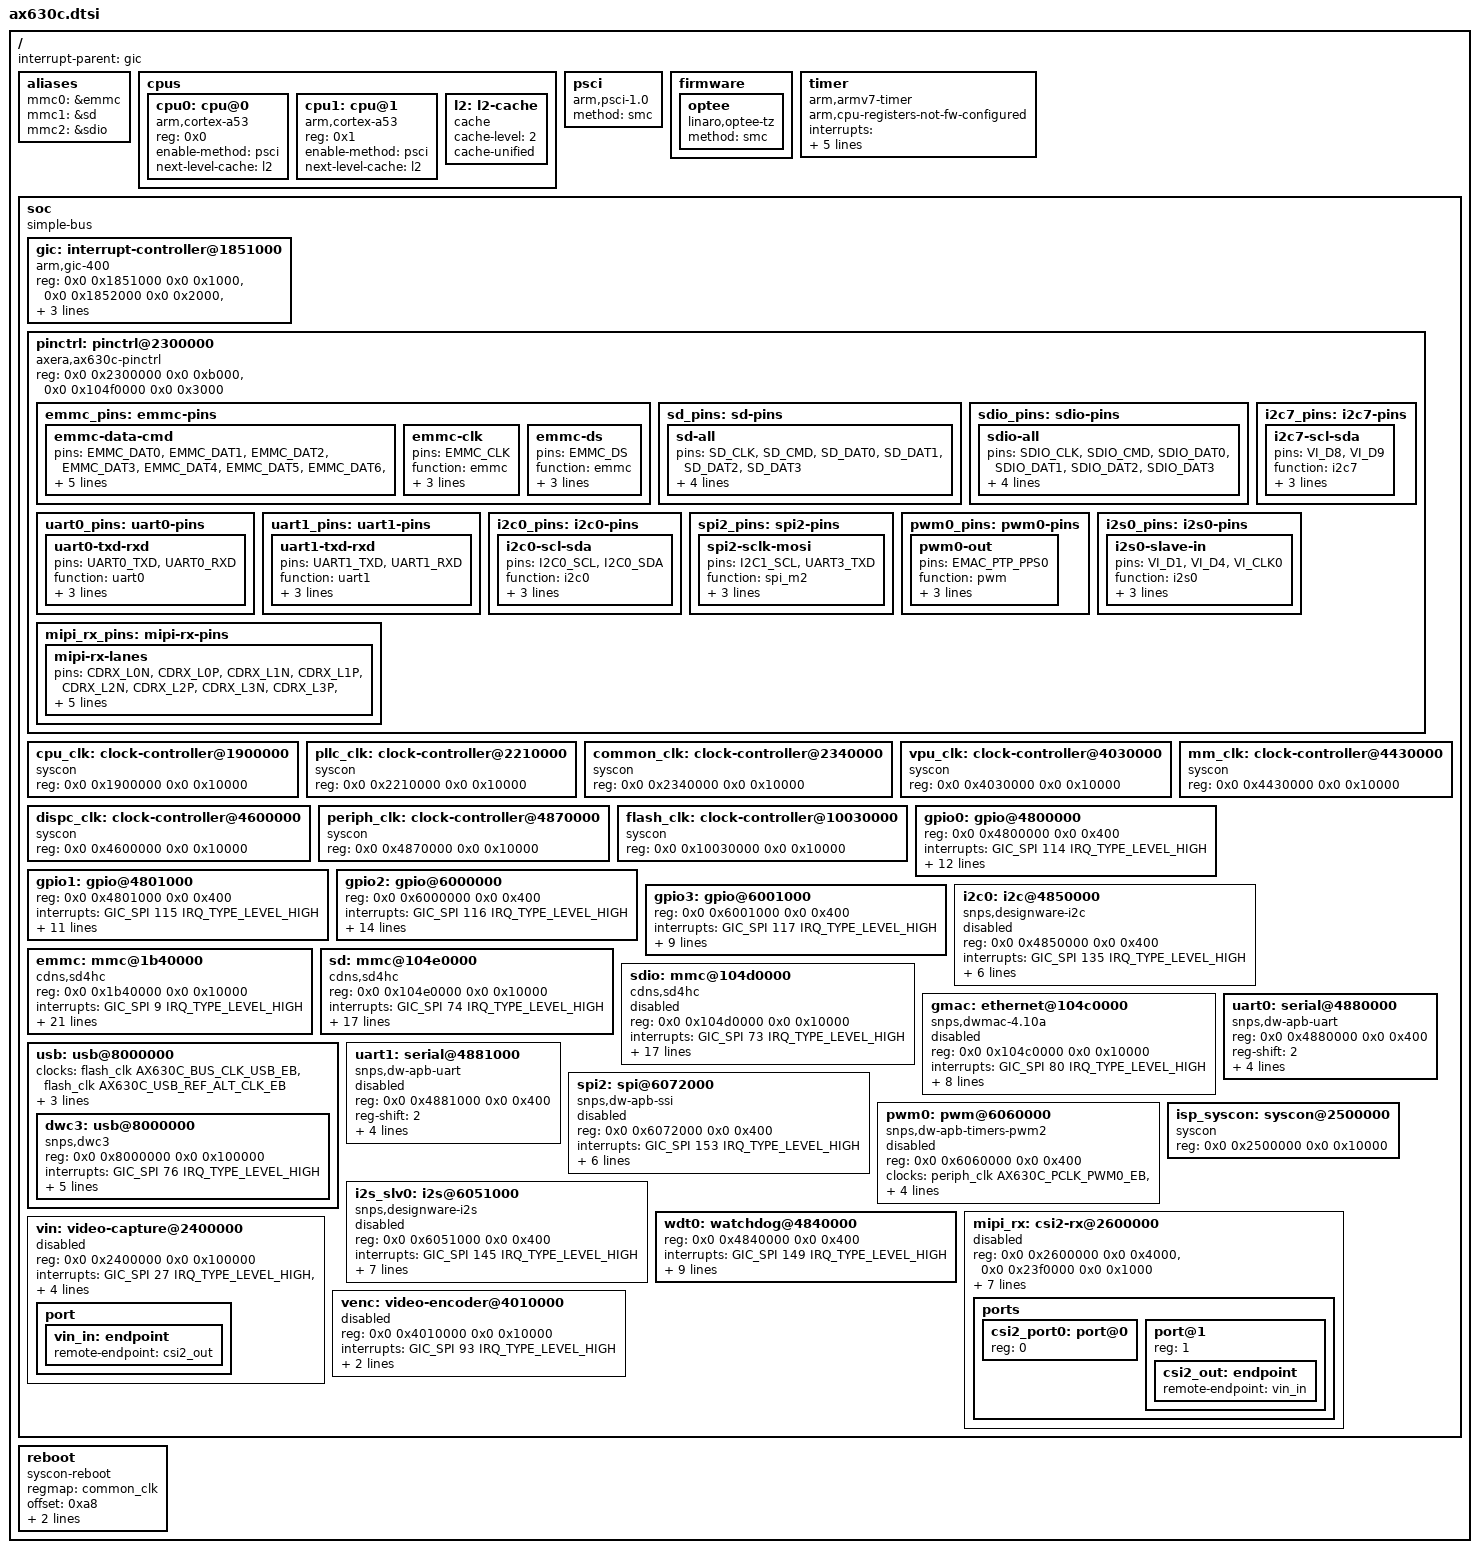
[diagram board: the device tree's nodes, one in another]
// SPDX-License-Identifier: GPL-2.0
/*
 * Axera AX630C (AX620E family) -- minimal mainline SoC description (#74).
 *
 * Written from the vendor GPL device tree
 * (maix_ax620e_sdk_kernel, arch/arm64/boot/dts/axera/AX620E.dtsi) and the
 * inventory in docs/mainline-port.md section 2. Register windows, interrupt
 * numbers and the 24 MHz timer rate are taken verbatim from that source; the
 * bindings are mainline ones.
 *
 * DELIBERATELY MINIMAL. A node arrives with the child issue that ports its
 * driver, because a node whose driver does not exist is a DT that lies. So far
 * that is #76 storage, #77 net, #80 clk/pinctrl, #81 GPIO/I2C and #82 USB;
 * video (#83) and display/audio (#84) are still absent.
 */

#include <dt-bindings/interrupt-controller/arm-gic.h>
#include <dt-bindings/clock/ax630c-clock.h>
#include <dt-bindings/reset/ax630c-reset.h>
#include "ax630c-compat.h"

/ {
	compatible = AX630C_SOC_COMPAT, AX620E_FAMILY_COMPAT;
	interrupt-parent = <&gic>;
	#address-cells = <2>;
	#size-cells = <2>;

	/*
	 * mmc aliases pin the MMC host indices, and on this board that is not
	 * cosmetic -- it decides whether the eMMC has a partition table at all.
	 *
	 * The eMMC's layout comes from the `blkdevparts=mmcblk0:...` clause of
	 * the U-Boot command line (there is no on-disk partition table), and
	 * that clause binds the table to a device NAME. The three SD4HC
	 * instances probe concurrently, so without aliases the eMMC is
	 * sometimes mmc0 and sometimes mmc1 -- and when it loses, `mmcblk0` is
	 * the empty SD slot, the table lands on nothing, and the eMMC comes up
	 * with zero partitions. Measured on hardware during #78: two slot-B
	 * boots out of five came up that way, and stage 1 could not find a
	 * rootfs on a board whose rootfs was perfectly intact.
	 *
	 * With these, mmc_of_parse()'s alias id fixes each host's index, the
	 * eMMC is always mmc0/mmcblk0, and the cmdline table always lands on
	 * it. #76 saw the same silicon behave because it happened to win.
	 */
	aliases {
		mmc0 = &emmc;
		mmc1 = &sd;
		mmc2 = &sdio;
	};

	cpus {
		#address-cells = <1>;
		#size-cells = <0>;

		cpu0: cpu@0 {
			device_type = "cpu";
			compatible = "arm,cortex-a53";
			reg = <0x0>;
			enable-method = "psci";
			next-level-cache = <&l2>;
		};

		cpu1: cpu@1 {
			device_type = "cpu";
			compatible = "arm,cortex-a53";
			reg = <0x1>;
			enable-method = "psci";
			next-level-cache = <&l2>;
		};

		l2: l2-cache {
			compatible = "cache";
			cache-level = <2>;
			cache-unified;
		};
	};

	/*
	 * TF-A 2.7 (plat/axera/ax620e) sits at 0x40040000 and MUST stay
	 * reserved no-map, or secondary CPU bring-up dies. Its plat_psci_ops
	 * implements no system_off/system_reset -- reboot comes from the
	 * watchdog restart handler instead (#75).
	 */
	psci {
		compatible = "arm,psci-1.0";
		method = "smc";
	};

	firmware {
		optee {
			compatible = "linaro,optee-tz";
			method = "smc";
		};
	};

	/*
	 * arm,armv7-timer with arm,cpu-registers-not-fw-configured: the
	 * firmware does not program CNTFRQ, so the 24 MHz clock-frequency here
	 * is load-bearing. Both properties are carried over verbatim.
	 */
	timer {
		compatible = "arm,armv7-timer";
		arm,cpu-registers-not-fw-configured;
		interrupts = <GIC_PPI 13 (GIC_CPU_MASK_SIMPLE(2) | IRQ_TYPE_LEVEL_HIGH)>,
			     <GIC_PPI 14 (GIC_CPU_MASK_SIMPLE(2) | IRQ_TYPE_LEVEL_HIGH)>,
			     <GIC_PPI 11 (GIC_CPU_MASK_SIMPLE(2) | IRQ_TYPE_LEVEL_HIGH)>,
			     <GIC_PPI 10 (GIC_CPU_MASK_SIMPLE(2) | IRQ_TYPE_LEVEL_HIGH)>;
		clock-frequency = <24000000>;
	};

	/*
	 * No PMU node. The vendor tree has none, so the PMU SPI numbers are
	 * simply not known from source -- inventing them would be worse than
	 * having no perf. Determine them on hardware and add the node then.
	 */

	soc {
		compatible = "simple-bus";
		#address-cells = <2>;
		#size-cells = <2>;
		ranges;

		/*
		 * GIC-400 (GICv2). The vendor node gives GICC a 0x1000 window;
		 * mainline's arm,gic-400 binding wants 0x2000 so GICC_DIR at
		 * +0x1000 is mapped for split EOI. 0x1852000 + 0x2000 stops
		 * short of GICH at 0x1854000, so widening it is safe.
		 */
		gic: interrupt-controller@1851000 {
			compatible = "arm,gic-400";
			reg = <0x0 0x1851000 0x0 0x1000>,	/* GICD */
			      <0x0 0x1852000 0x0 0x2000>,	/* GICC */
			      <0x0 0x1854000 0x0 0x2000>,	/* GICH */
			      <0x0 0x1856000 0x0 0x2000>;	/* GICV */
			interrupt-controller;
			#interrupt-cells = <3>;
		};

		/*
		 * Clock controllers (#80). Grouped rather than scattered
		 * through the address ordering, because they are one driver
		 * and one data model: the register maps and per-clock tables
		 * are docs/reference/mainline/clk-model-20260906.md, which was
		 * reconciled clock by clock against a running device.
		 *
		 * Every window is 64 KiB and every one is also a syscon. The
		 * eight here register 279 clocks between them; the vendor's
		 * ninth ("isp") is omitted because no driver has ever
		 * implemented it, as is the whole ddr namespace.
		 *
		 * Seven of the eight also hand out reset lines -- 148 of them,
		 * one bit each in the words next to the clock gates, described
		 * in docs/reference/mainline/reset-model-20260906.md. They get
		 * #reset-cells here rather than reset-controller@ nodes of
		 * their own: a second node over the same window would mean a
		 * second regmap and a second lock over registers the clock
		 * driver read-modify-writes. pllc has no reset lines.
		 *
		 * No node carries assigned-clocks yet. The bootloader leaves
		 * the tree in a working state -- CPUPLL locked at 1.2 GHz, the
		 * UART fed from cpll_208m, the Ethernet refs already selected
		 * -- and a first mainline boot should change nothing it does
		 * not have to.
		 */
		/*
		 * Pin controller (#80). 111 pads in two windows that form one
		 * logical offset space; the driver keeps each pad's offset
		 * local to its own window rather than reproducing the vendor's
		 * SECOND_OFFSET arithmetic.
		 *
		 * The states below are transcribed from the vendor boot
		 * chain's own pad table (pinctrl-model section 4.2), which is
		 * what actually programs these pads today: 133 writes, 111 of
		 * them one per pad, issued by U-Boot before Linux starts. They
		 * are therefore no-ops in value on this board -- the point of
		 * writing them down is that Linux now OWNS the pads it uses,
		 * so a pad cannot be silently re-muxed out from under a driver
		 * and a second claimant gets -EBUSY instead of a corrupted
		 * bus. Only nodes that exist get a state; the rest arrive with
		 * their drivers (#77 RGMII, #83/#84 video). USB
		 * arrived without one on purpose -- its only pin group is the
		 * host-mode OVRCUR/POWER_EN pair, which this board does not
		 * wire; see the usb node below.
		 *
		 * Three rules the driver enforces, worth knowing before adding
		 * one:
		 *
		 *  - Config properties must name `pins`, never `groups`: the
		 *    driver implements pin_config_set and not
		 *    pin_config_group_set, and the core fails the whole state
		 *    (and the consumer's probe) on the latter.
		 *  - The multi-pad groups are wider than they look. "uart0"
		 *    includes two RGMII pads as CTS/RTS and "uart1" includes
		 *    EMMC_PWR_EN and BOND2, so the UART states below name
		 *    their two pads explicitly.
		 *  - drive-strength is the pad's raw 4-bit code, not mA. The
		 *    mA mapping is not known for this SoC.
		 *
		 * axera,dphytx-reset / axera,dphytx-mipien are deliberately
		 * absent, and the syscon holding the MIPI-enable bit has no node
		 * until the video stack lands (#83). That gates set_mux() only:
		 * a CDTX_* pad cannot be moved off function 0 by a pinctrl state
		 * without parking the transmitter first. gpio_request_enable()
		 * does not park, and #81 muxes three of those pads to GPIO
		 * through it on every boot -- which is exactly what the vendor's
		 * own LT6911 driver has always done with a raw register write,
		 * so it is the proven path rather than a shortcut.
		 */
		pinctrl: pinctrl@2300000 {
			compatible = "axera,ax630c-pinctrl";
			reg = <0x0 0x2300000 0x0 0xb000>,
			      <0x0 0x104f0000 0x0 0x3000>;

			/*
			 * eMMC, three electrical variants. EMMC_RESET_N is
			 * deliberately not here: it is not part of function
			 * emmc at all (the pad has no function 0), it is the
			 * card's RST_n driven as GPIO2_A23, and it belongs to
			 * the reset-gpios TODO on the mmc node (#81).
			 *
			 * The vendor's own DT pin group for EMMC_CMD says
			 * pull-DOWN where its boot table writes pull-up. The
			 * boot table wins here: it is what has been running on
			 * this board, and that DT group is one of the ones the
			 * board dts never references.
			 */
			emmc_pins: emmc-pins {
				emmc-data-cmd {
					pins = "EMMC_DAT0", "EMMC_DAT1",
					       "EMMC_DAT2", "EMMC_DAT3",
					       "EMMC_DAT4", "EMMC_DAT5",
					       "EMMC_DAT6", "EMMC_DAT7",
					       "EMMC_CMD";
					function = "emmc";
					drive-strength = <3>;
					bias-pull-up;
					input-schmitt-disable;
				};

				emmc-clk {
					pins = "EMMC_CLK";
					function = "emmc";
					drive-strength = <3>;
					bias-disable;
					input-schmitt-disable;
				};

				/* Data strobe: pulled down, per the boot table. */
				emmc-ds {
					pins = "EMMC_DS";
					function = "emmc";
					drive-strength = <3>;
					bias-pull-down;
					input-schmitt-disable;
				};
			};

			sd_pins: sd-pins {
				sd-all {
					pins = "SD_CLK", "SD_CMD", "SD_DAT0",
					       "SD_DAT1", "SD_DAT2", "SD_DAT3";
					function = "sd";
					drive-strength = <5>;
					bias-disable;
					input-schmitt-disable;
				};
			};

			sdio_pins: sdio-pins {
				sdio-all {
					pins = "SDIO_CLK", "SDIO_CMD",
					       "SDIO_DAT0", "SDIO_DAT1",
					       "SDIO_DAT2", "SDIO_DAT3";
					function = "sdio";
					drive-strength = <8>;
					bias-disable;
					input-schmitt-disable;
				};
			};

			/*
			 * Two pads each, not the four-pad "uart0"/"uart1"
			 * groups: this board wires no flow control, and those
			 * groups would claim two RGMII pads and two pads the
			 * board uses for other things.
			 */
			uart0_pins: uart0-pins {
				uart0-txd-rxd {
					pins = "UART0_TXD", "UART0_RXD";
					function = "uart0";
					drive-strength = <3>;
					bias-pull-up;
					input-schmitt-disable;
				};
			};

			uart1_pins: uart1-pins {
				uart1-txd-rxd {
					pins = "UART1_TXD", "UART1_RXD";
					function = "uart1";
					drive-strength = <3>;
					bias-pull-up;
					input-schmitt-disable;
				};
			};

			/*
			 * The two I2C buses this board actually uses: i2c0
			 * carries the LT6911UXC HDMI-RX bridge, i2c7 the
			 * touch controller. These are exactly the states the
			 * vendor board dts /delete-property/s -- along with
			 * the "gpio" bus-recovery state, which left its
			 * i2c-gpio recovery claiming GPIOs it could never
			 * mux, so recovery bit-banged pads still wired to the
			 * I2C controller.
			 *
			 * Declared but not referenced: there is no I2C
			 * controller node until that driver is ported, and a
			 * node whose driver does not exist is a DT that lies.
			 * Bus recovery wants the matching "gpio" state, which
			 * needs #81. i2c1 and i2c6 are deliberately absent:
			 * their pads belong to spi1/spi2/i2s_slv0 on this
			 * board, and with strict mux enforcement the second
			 * claimant would simply fail.
			 */
			i2c0_pins: i2c0-pins {
				i2c0-scl-sda {
					pins = "I2C0_SCL", "I2C0_SDA";
					function = "i2c0";
					drive-strength = <3>;
					bias-pull-up;
					input-schmitt-disable;
				};
			};

			i2c7_pins: i2c7-pins {
				i2c7-scl-sda {
					pins = "VI_D8", "VI_D9";
					function = "i2c7";
					drive-strength = <3>;
					bias-pull-up;
					input-schmitt-disable;
				};
			};

			/*
			 * The MIPI CSI-2 receiver's twelve lane pads (#83).
			 * Six differential pairs; the board uses four of them
			 * for data and one for the clock, and the D-PHY's own
			 * lane-swap fields decide which is which -- so the
			 * whole group is claimed, not a subset.
			 *
			 * Every value here reproduces what the boot chain's own
			 * pad table writes: 0x00000000, which is mux 0
			 * (dphy_rx, the pads' only real function), drive code
			 * 0, no pull, no schmitt. That is also the pads' reset
			 * state, so this state is a no-op in value on this
			 * board. The point is OWNERSHIP: on 4.19 the vendor
			 * boot chain and then ax_pinmux replayed the SDK pad
			 * table, and nothing replays it on mainline.
			 *
			 * VI_D7 is deliberately absent, and so is every other
			 * VI_* pad. VI_D7 carries SW_PWR (GPIO0_A7) on this
			 * board -- the vendor capture stack re-muxed it at
			 * every pipeline init and that is the whole SW_PWR
			 * trap. The MIPI path does not need it.
			 */
			/*
			 * SPI2, the mini-display's bus (#84). TWO pads, not
			 * four: the panel is write-only, so MISO is not
			 * claimed, and the chip select is a GPIO -- the pad
			 * that would carry SPI_M2_CS0 (I2C1_SDA) is muxed to
			 * GPIO0_A27 by the GPIO claim instead, which is what
			 * the vendor board does too.
			 *
			 * Drive strength 3 and a pull-up on both, reproducing
			 * the boot chain's own pad table. The SSI clock is
			 * 208 MHz and the panel is asked for 80, so the bus
			 * actually runs at 52 -- spi-dw's divisor is even.
			 */
			spi2_pins: spi2-pins {
				spi2-sclk-mosi {
					pins = "I2C1_SCL", "UART3_TXD";
					function = "spi_m2";
					drive-strength = <3>;
					bias-pull-up;
					input-schmitt-disable;
				};
			};

			/*
			 * The backlight's PWM output (#84): PWM0 channel 0 on
			 * its alternate pad (function PWM0_M), which is what
			 * the vendor group `emac_ptp_pps0_pwm0_m_pins` names.
			 *
			 * THIS ONE IS NOT A NO-OP IN VALUE, unlike most of the
			 * states in this file. The boot chain's own pad table
			 * leaves EMAC_PTP_PPS0 muxed to GPIO1_A8
			 * (0x104F000C = 0x00060003) and the vendor KERNEL is
			 * what moves it to PWM at probe -- measured on the
			 * running vendor system as 0x00020003, which is
			 * exactly what this state writes. Nothing replays that
			 * on mainline, so without this group the backlight pad
			 * stays an unclaimed GPIO and the panel is dark with a
			 * PWM that reports itself working.
			 *
			 * No pull: the pad drives a load, it is never read.
			 */
			pwm0_pins: pwm0-pins {
				pwm0-out {
					pins = "EMAC_PTP_PPS0";
					function = "pwm";
					drive-strength = <3>;
					bias-disable;
					input-schmitt-disable;
				};
			};

			/*
			 * The HDMI audio port's three pads (#84). Capture
			 * only, so no DOUT and no MCLK: the LT6911UXC is the
			 * bit-clock and frame master and the SoC is a pure
			 * slave.
			 *
			 * DIN1, not DIN0. The peripheral syscon's audio
			 * crossbar word puts this stream on the slave block's
			 * RX channel 1 (see the i2s node below), and the pad
			 * that feeds channel 1 is VI_D4.
			 *
			 * These three pads are VI_* like SW_PWR's VI_D7, and
			 * the same rule applies: claim only what is used, and
			 * never VI_D7.
			 */
			i2s0_pins: i2s0-pins {
				i2s0-slave-in {
					pins = "VI_D1", "VI_D4", "VI_CLK0";
					function = "i2s0";
					drive-strength = <3>;
					bias-disable;
					input-schmitt-disable;
				};
			};

			mipi_rx_pins: mipi-rx-pins {
				mipi-rx-lanes {
					pins = "CDRX_L0N", "CDRX_L0P",
					       "CDRX_L1N", "CDRX_L1P",
					       "CDRX_L2N", "CDRX_L2P",
					       "CDRX_L3N", "CDRX_L3P",
					       "CDRX_L4N", "CDRX_L4P",
					       "CDRX_L5N", "CDRX_L5P";
					function = "dphy_rx";
					drive-strength = <0>;
					bias-disable;
					input-schmitt-disable;
				};
			};
		};

		cpu_clk: clock-controller@1900000 {
			compatible = AX630C_CPU_CLK_COMPAT, "syscon";
			reg = <0x0 0x1900000 0x0 0x10000>;
			#clock-cells = <1>;
			#reset-cells = <1>;
		};

		pllc_clk: clock-controller@2210000 {
			compatible = AX630C_PLLC_CLK_COMPAT, "syscon";
			reg = <0x0 0x2210000 0x0 0x10000>;
			#clock-cells = <1>;
		};

		common_clk: clock-controller@2340000 {
			compatible = AX630C_COMMON_CLK_COMPAT, "syscon";
			reg = <0x0 0x2340000 0x0 0x10000>;
			#clock-cells = <1>;
			#reset-cells = <1>;
		};

		vpu_clk: clock-controller@4030000 {
			compatible = AX630C_VPU_CLK_COMPAT, "syscon";
			reg = <0x0 0x4030000 0x0 0x10000>;
			#clock-cells = <1>;
			#reset-cells = <1>;
		};

		mm_clk: clock-controller@4430000 {
			compatible = AX630C_MM_CLK_COMPAT, "syscon";
			reg = <0x0 0x4430000 0x0 0x10000>;
			#clock-cells = <1>;
			#reset-cells = <1>;
		};

		dispc_clk: clock-controller@4600000 {
			compatible = AX630C_DISPC_CLK_COMPAT, "syscon";
			reg = <0x0 0x4600000 0x0 0x10000>;
			#clock-cells = <1>;
			#reset-cells = <1>;
		};

		periph_clk: clock-controller@4870000 {
			compatible = AX630C_PERIPH_CLK_COMPAT, "syscon";
			reg = <0x0 0x4870000 0x0 0x10000>;
			#clock-cells = <1>;
			#reset-cells = <1>;
		};

		flash_clk: clock-controller@10030000 {
			compatible = AX630C_FLASH_CLK_COMPAT, "syscon";
			reg = <0x0 0x10030000 0x0 0x10000>;
			#clock-cells = <1>;
			#reset-cells = <1>;
		};

		/*
		 * GPIO (#81). Four identical 32-line controllers; the block is
		 * DesignWare in its register names only, so gpio-dwapb cannot
		 * bind and drivers/gpio/gpio-ax630c.c exists.
		 *
		 * gpio-ranges is the load-bearing property here, not
		 * decoration. It is what makes gpiochip_generic_request() reach
		 * the pin controller's gpio_request_enable(), which programs
		 * the pad's mux -- the root fix for the SW_PWR trap, where
		 * exporting a GPIO never reprogrammed the pad and the value
		 * register echoed a latch that no longer reached a ball. The
		 * mapping is not an identity: 97 of the 111 pads reach a GPIO
		 * line, in seven runs per controller, and lines outside those
		 * runs exist in the register file but reach no pad. The runs
		 * below are the vendor DT's 97 single-line entries collapsed,
		 * pin for pin.
		 *
		 * Two clocks each: "gpio" drives the per-line debounce filter
		 * and the interrupt synchroniser, "apb" the register file.
		 * Two resets each, deasserted at probe and never pulsed --
		 * lines on these blocks drive the host's ATX power button and
		 * the HDMI receiver's power rails, so a reset pulse would be a
		 * keystroke nobody pressed.
		 */
		gpio0: gpio@4800000 {
			compatible = AX630C_GPIO_COMPAT;
			reg = <0x0 0x4800000 0x0 0x400>;
			interrupts = <GIC_SPI 114 IRQ_TYPE_LEVEL_HIGH>;
			clocks = <&periph_clk AX630C_CLK_GPIO0_EB>,
				 <&periph_clk AX630C_PCLK_GPIO0_EB>;
			clock-names = "gpio", "apb";
			resets = <&periph_clk AX630C_RST_PERIPH_AX_GPIO0_GPIO_PRST>,
				 <&periph_clk AX630C_RST_PERIPH_AX_GPIO0_GPIO>;
			reset-names = "apb", "gpio";
			gpio-controller;
			#gpio-cells = <2>;
			ngpios = <32>;
			gpio-ranges = <&pinctrl 0 0 11>, <&pinctrl 11 79 4>,
				      <&pinctrl 15 87 4>, <&pinctrl 19 62 1>,
				      <&pinctrl 20 60 1>, <&pinctrl 21 92 3>,
				      <&pinctrl 24 11 8>;
			interrupt-controller;
			#interrupt-cells = <2>;
			status = "okay";
		};

		gpio1: gpio@4801000 {
			compatible = AX630C_GPIO_COMPAT;
			reg = <0x0 0x4801000 0x0 0x400>;
			interrupts = <GIC_SPI 115 IRQ_TYPE_LEVEL_HIGH>;
			clocks = <&periph_clk AX630C_CLK_GPIO1_EB>,
				 <&periph_clk AX630C_PCLK_GPIO1_EB>;
			clock-names = "gpio", "apb";
			resets = <&periph_clk AX630C_RST_PERIPH_AX_GPIO1_GPIO_PRST>,
				 <&periph_clk AX630C_RST_PERIPH_AX_GPIO1_GPIO>;
			reset-names = "apb", "gpio";
			gpio-controller;
			#gpio-cells = <2>;
			ngpios = <32>;
			gpio-ranges = <&pinctrl 0 19 4>, <&pinctrl 4 95 4>,
				      <&pinctrl 8 23 4>, <&pinctrl 12 33 12>,
				      <&pinctrl 24 27 6>, <&pinctrl 30 63 2>;
			interrupt-controller;
			#interrupt-cells = <2>;
			status = "okay";
		};

		gpio2: gpio@6000000 {
			compatible = AX630C_GPIO_COMPAT;
			reg = <0x0 0x6000000 0x0 0x400>;
			interrupts = <GIC_SPI 116 IRQ_TYPE_LEVEL_HIGH>;
			clocks = <&periph_clk AX630C_CLK_GPIO2_EB>,
				 <&periph_clk AX630C_PCLK_GPIO2_EB>;
			clock-names = "gpio", "apb";
			resets = <&periph_clk AX630C_RST_PERIPH_AX_GPIO2_GPIO_PRST>,
				 <&periph_clk AX630C_RST_PERIPH_AX_GPIO2_GPIO>;
			reset-names = "apb", "gpio";
			gpio-controller;
			#gpio-cells = <2>;
			ngpios = <32>;
			/* 30 pads, not 32: lines 30 and 31 reach nothing. */
			gpio-ranges = <&pinctrl 0 65 4>, <&pinctrl 4 45 6>,
				      <&pinctrl 10 69 10>, <&pinctrl 20 56 1>,
				      <&pinctrl 21 54 1>, <&pinctrl 22 55 1>,
				      <&pinctrl 23 52 1>, <&pinctrl 24 51 1>,
				      <&pinctrl 25 53 1>, <&pinctrl 26 57 3>,
				      <&pinctrl 29 61 1>;
			interrupt-controller;
			#interrupt-cells = <2>;
			status = "okay";
		};

		gpio3: gpio@6001000 {
			compatible = AX630C_GPIO_COMPAT;
			reg = <0x0 0x6001000 0x0 0x400>;
			interrupts = <GIC_SPI 117 IRQ_TYPE_LEVEL_HIGH>;
			clocks = <&periph_clk AX630C_CLK_GPIO3_EB>,
				 <&periph_clk AX630C_PCLK_GPIO3_EB>;
			clock-names = "gpio", "apb";
			resets = <&periph_clk AX630C_RST_PERIPH_AX_GPIO3_GPIO_PRST>,
				 <&periph_clk AX630C_RST_PERIPH_AX_GPIO3_GPIO>;
			reset-names = "apb", "gpio";
			gpio-controller;
			#gpio-cells = <2>;
			ngpios = <32>;
			/* Three pads, on lines 1-3. Line 0 reaches nothing. */
			gpio-ranges = <&pinctrl 1 84 3>;
			interrupt-controller;
			#interrupt-cells = <2>;
			status = "okay";
		};

		/*
		 * I2C0 (#81), the bus the LT6911UXC HDMI receiver lives on.
		 * Stock Synopsys DesignWare; mainline i2c-designware-platform
		 * binds the unmodified compatible.
		 *
		 * The vendor driver hard-codes 208 MHz as its timing input and
		 * programs the source mux itself. Naming the clock instead
		 * means i2c-designware computes HCNT/LCNT from
		 * clk_get_rate(), so the bus is right whatever source firmware
		 * selected -- and clk_i2c_sel is registered precisely so that
		 * rate is a fact rather than a constant.
		 *
		 * The "gpio" bus-recovery state is deliberately absent. The
		 * vendor's recovery claims GPIO0_A24/A25 while its pinctrl
		 * states leave those pads on the I2C controller, so it
		 * bit-bangs pads the controller still owns -- recovery that
		 * cannot work. Doing it properly needs scl-gpios/sda-gpios and
		 * a matching pin state, which is worth adding the day a stuck
		 * bus is actually observed.
		 */
		i2c0: i2c@4850000 {
			compatible = "snps,designware-i2c";
			reg = <0x0 0x4850000 0x0 0x400>;
			interrupts = <GIC_SPI 135 IRQ_TYPE_LEVEL_HIGH>;
			clocks = <&periph_clk AX630C_CLK_I2C_MST0_EB>,
				 <&periph_clk AX630C_PCLK_I2C_MST0_EB>;
			clock-names = "ref", "pclk";
			resets = <&periph_clk AX630C_RST_PERIPH_I2C0>;
			pinctrl-names = "default";
			pinctrl-0 = <&i2c0_pins>;
			clock-frequency = <400000>;
			i2c-sda-hold-time-ns = <500>;
			#address-cells = <1>;
			#size-cells = <0>;
			status = "disabled";
		};

		/*
		 * eMMC (#76) -- the boot device. Everything about this node is
		 * argued in docs/reference/mainline/sdhci-model-20260906.md;
		 * the four things a reader will want to know are:
		 *
		 * NO `resets`, deliberately. The SoC does have three reset
		 * lines for this controller (prst/arst/cardrst, cpu syscon
		 * 0x10 bits 12/12/11) but mainline sdhci-cadence reserves the
		 * `resets` property for the CARD's RST_n and binds index 0 to
		 * card_hw_reset. Listing the controller's own APB reset there
		 * makes mmc_hw_reset() -- an error-recovery path -- reset the
		 * host. It would pass a first boot and wedge under I/O error
		 * days later. Firmware leaves all three deasserted (U-Boot
		 * reads the kernel through this controller), so doing nothing
		 * is correct.
		 *
		 * ONE clock. The binding allows exactly one and the driver
		 * takes index 0 unnamed, so it is the card clock. The
		 * controller's own bus gate (AX630C_CLK_EMMC_EB) cannot be
		 * named here and is CLK_IS_CRITICAL in the clock driver.
		 *
		 * NO `sdhci-caps-mask`. The vendor's <0x2 0x03200000> clears
		 * CAN_VDD_330|CAN_VDD_300|CAN_DO_HISPD, all of which the
		 * cap-* properties below then re-add. It is redundant, not
		 * dangerous -- CAPS0 reads 0x176AC8B2 on this silicon, so
		 * CAN_VDD_180 survives the mask and ocr_avail is non-zero
		 * either way (measured 2026-09-06).
		 *
		 * NO cdns,phy-input-delay-mmc-legacy. PHY address 0x06 has no
		 * entry in any driver's property table, vendor included, so
		 * the vendor DT's value has never been applied to this board.
		 * Upstream's schema is unevaluatedProperties:false.
		 *
		 * TODO(#81): cap-mmc-hw-reset + reset-gpios = <&gpio2 23
		 * GPIO_ACTIVE_LOW>. The card's real RST_n is GPIO2_A23, and
		 * with CONFIG_RESET_GPIO the reset core synthesises a
		 * controller over it for free -- but there is no GPIO
		 * controller node until #81, and a phandle to a node that does
		 * not exist does not compile.
		 */
		emmc: mmc@1b40000 {
			compatible = AX630C_SDHCI_COMPAT, "cdns,sd4hc";
			reg = <0x0 0x1b40000 0x0 0x10000>;
			interrupts = <GIC_SPI 9 IRQ_TYPE_LEVEL_HIGH>;
			clocks = <&cpu_clk AX630C_CLK_EMMC_CARD_EB>;
			pinctrl-names = "default";
			pinctrl-0 = <&emmc_pins>;
			bus-width = <8>;
			non-removable;
			no-sd;
			no-sdio;
			disable-wp;
			cap-mmc-highspeed;
			/*
			 * This logs "mmc0: invalid driver type, default to
			 * driver type B" a few times per boot, and that is
			 * correct behaviour, not a defect to chase.
			 * fixed-emmc-driver-type carries an eMMC-spec driver
			 * type (table 206); 4 = 40 ohm. sdhci can only express
			 * the SD host types A/B/C/D = 0..3, so it warns and
			 * uses B -- while the CARD is still programmed to type
			 * 4 through EXT_CSD_HS_TIMING. The vendor's own driver
			 * has the identical limitation, so keeping the property
			 * reproduces the vendor's proven electrical state
			 * exactly; dropping it would quiet the log and change
			 * the card's drive strength.
			 */
			fixed-emmc-driver-type = <4>;
			/*
			 * Pinned to high speed for bring-up, on purpose.
			 * Mainline runs a read-gap tuning step over HRS37/HRS38
			 * (0x94/0x98) for HS200+, and those registers appear in
			 * NO AX630C source -- not the vendor kernel, not the
			 * SPL, not U-Boot. If they are unimplemented the tuning
			 * loop degrades harmlessly, but a 16-iteration retry
			 * storm could outlast U-Boot's 30 s watchdog and look
			 * exactly like a crash on a board with no console.
			 *
			 * TODO(#76): once this has booted, restore
			 * max-frequency = <200000000> plus mmc-hs200-1_8v,
			 * mmc-hs400-1_8v and mmc-hs400-enhanced-strobe, and the
			 * HS400ES path (which mainline already implements
			 * identically to the vendor) comes back with them.
			 */
			max-frequency = <50000000>;
			cdns,phy-input-delay-sd-highspeed = <2>;
			cdns,phy-input-delay-legacy = <4>;
			cdns,phy-input-delay-sd-uhs-sdr12 = <1>;
			cdns,phy-input-delay-sd-uhs-sdr25 = <2>;
			cdns,phy-input-delay-sd-uhs-sdr50 = <1>;
			cdns,phy-input-delay-sd-uhs-ddr50 = <2>;
			cdns,phy-input-delay-mmc-highspeed = <2>;
			cdns,phy-input-delay-mmc-ddr = <2>;
			cdns,phy-dll-delay-sdclk = <45>;
			cdns,phy-dll-delay-sdclk-hsmmc = <31>;
			cdns,phy-dll-delay-strobe = <18>;
			status = "okay";
		};

		/*
		 * SD card slot (#76). Not on the boot path; this is where a
		 * mainline rootfs goes, which is why it is enabled before
		 * anything needs it.
		 *
		 * no-1-8-v is a deliberate cap, not an oversight. UHS on this
		 * board needs the pad I/O-voltage domain switched in pin-group
		 * G9's MISC0 word (0x104F1004/8 bits [8:7], with a rail-detect
		 * read at 0x104F1058) -- something no upstream code does and
		 * the vqmmc-regulator model cannot express. Without the switch
		 * a card that negotiates 1.8 V signalling would be talking to
		 * 3.3 V pads. With this property the slot runs default/high
		 * speed to 50 MHz, correctly.
		 */
		sd: mmc@104e0000 {
			compatible = AX630C_SDHCI_COMPAT, "cdns,sd4hc";
			reg = <0x0 0x104e0000 0x0 0x10000>;
			interrupts = <GIC_SPI 74 IRQ_TYPE_LEVEL_HIGH>;
			clocks = <&flash_clk AX630C_CLK_SD_CARD_EB>;
			pinctrl-names = "default";
			pinctrl-0 = <&sd_pins>;
			max-frequency = <50000000>;
			bus-width = <4>;
			no-mmc;
			no-sdio;
			no-1-8-v;
			disable-wp;
			broken-cd;
			cap-sd-highspeed;
			cdns,phy-input-delay-sd-highspeed = <2>;
			cdns,phy-input-delay-legacy = <3>;
			cdns,phy-input-delay-sd-uhs-sdr12 = <3>;
			cdns,phy-input-delay-sd-uhs-sdr25 = <2>;
			cdns,phy-input-delay-sd-uhs-sdr50 = <1>;
			cdns,phy-input-delay-sd-uhs-ddr50 = <1>;
			cdns,phy-dll-delay-sdclk = <0>;
			status = "okay";
		};

		/*
		 * SDIO -- the aic8800 Wi-Fi (#85), and the only closed content
		 * this project still allows (firmware, not driver). Described
		 * because it is the same IP as the two above and costs nothing
		 * to get right now, disabled because #76 wants one fewer thing
		 * to go wrong on a console-less first boot.
		 */
		sdio: mmc@104d0000 {
			compatible = AX630C_SDHCI_COMPAT, "cdns,sd4hc";
			reg = <0x0 0x104d0000 0x0 0x10000>;
			interrupts = <GIC_SPI 73 IRQ_TYPE_LEVEL_HIGH>;
			clocks = <&flash_clk AX630C_CLK_SDIO_M_CARD_EB>;
			pinctrl-names = "default";
			pinctrl-0 = <&sdio_pins>;
			max-frequency = <50000000>;
			bus-width = <4>;
			no-sd;
			no-mmc;
			no-1-8-v;
			disable-wp;
			broken-cd;
			cap-sd-highspeed;
			cdns,phy-input-delay-sd-highspeed = <4>;
			cdns,phy-input-delay-legacy = <3>;
			cdns,phy-input-delay-sd-uhs-sdr12 = <3>;
			cdns,phy-input-delay-sd-uhs-sdr25 = <2>;
			cdns,phy-input-delay-sd-uhs-sdr50 = <1>;
			cdns,phy-input-delay-sd-uhs-ddr50 = <1>;
			cdns,phy-dll-delay-sdclk = <0>;
			status = "disabled";
		};

		/*
		 * Ethernet MAC (#77) -- a stock Synopsys DWMAC 4.10a. The
		 * second compatible is not decoration: stmmac_probe_config_dt()
		 * keys DWMAC_CORE_GMAC4 and PMT off "snps,dwmac-4.10a", and
		 * dwmac-generic is linked last precisely so a vendor glue named
		 * first in the list wins the bind.
		 *
		 * FOUR clocks, not the vendor's five. "rmii_phy" drives the
		 * on-chip EPHY, which this board does not use and which
		 * firmware leaves both held in reset and shut down (flash
		 * syscon +0x14 bit 9 and +0x20 bit 0, measured 2026-09-06).
		 * A clock in this list is a clock the driver enables, so
		 * naming that one would power a block the board has no use for.
		 *
		 * NO `resets`. The vendor DT lists three (emac, ephy,
		 * ephy_shutdown) through a reset controller mainline does not
		 * have; the MAC's own block reset is one syscon bit and the
		 * glue pulses it at probe. The two EPHY lines are for the block
		 * above.
		 *
		 * Interrupt names: "macirq" only. The vendor node names three
		 * (macirq, eth_wake_irq, eth_lpi) against ONE interrupt, so the
		 * second and third resolve to the same line -- stmmac then
		 * treats the shared line as a wake source. One name, one line.
		 *
		 * Board-specific properties (phy-mode, the MDIO bus, the PHY
		 * reset line) are in the board dts; this node is the SoC.
		 */
		gmac: ethernet@104c0000 {
			compatible = AX630C_DWMAC_COMPAT, "snps,dwmac-4.10a";
			reg = <0x0 0x104c0000 0x0 0x10000>;
			interrupts = <GIC_SPI 80 IRQ_TYPE_LEVEL_HIGH>;
			interrupt-names = "macirq";
			clocks = <&flash_clk AX630C_ACLK_EMAC_EB>,
				 <&flash_clk AX630C_CLK_EMAC_PTP_REF_EB>,
				 <&flash_clk AX630C_CLK_EMAC_RGMII_TX_EB>,
				 <&flash_clk AX630C_EPHY_CLK_EB>;
			clock-names = "stmmaceth", "ptp_ref", "tx", "ephy";
			axera,flash-syscon = <&flash_clk>;
			rx-fifo-depth = <32768>;
			tx-fifo-depth = <16384>;
			snps,tso;
			status = "disabled";
		};

		/*
		 * USB 2.0 (#82) -- a stock Synopsys DWC3, high-speed only, and
		 * the reason this product exists: the port presents a keyboard,
		 * a mouse and a disk to the machine the KVM controls.
		 *
		 * TWO nodes, the dwc3-of-simple arrangement upstream uses for
		 * exactly this hardware shape (rockchip, xilinx, hisilicon).
		 * The outer node is the glue: it owns the three clock gates,
		 * the two software resets and the VBUSVALID bit, none of which
		 * live in the controller's own window. The inner node is the
		 * core, and mainline's dwc3 binds it unmodified.
		 *
		 * The split is not cosmetic. The core node names the 24 MHz
		 * reference as "ref" so dwc3_ref_clk_period() can derive
		 * GUCTL.REFCLKPER and the two GFLADJ fields from
		 * clk_get_rate() -- which lands on 0x29, 0x7f0 and 0xa, the
		 * three constants the vendor glue hardcodes. Handing the core
		 * `snps,ref-clock-period-ns` instead would set REFCLKPER right
		 * and the frequency adjustment to zero, because the core would
		 * believe the reference is 24.39 MHz rather than 24.
		 *
		 * dr_mode = "peripheral", not the vendor's "otg", and this is
		 * the configuration that was boot-tested and enumerated by a
		 * host. OTG here is ID detection on a raw GPIO (GPIO1_A4)
		 * through linux,extcon-usb-gpio. #81 has since landed a GPIO
		 * controller, so the node below is now writable -- but nothing
		 * on this board is ever plugged INTO this port, so peripheral
		 * stays the shipped mode and OTG is an untested addition
		 * waiting for a reason.
		 *
		 * TODO(#83/#84, if a reason appears): add
		 *   extcon_usb: extcon-usb {
		 *           compatible = "linux,extcon-usb-gpio";
		 *           id-gpios = <&gpio1 4 GPIO_ACTIVE_HIGH>;
		 *   };
		 * and put dr_mode = "otg"; extcon = <&extcon_usb>; on the core
		 * node. The glue already clears VBUSVALID for host mode; what
		 * it does not yet do is follow a role change at runtime, and
		 * the host-mode pin group below would have to be claimed too.
		 *
		 * No pinctrl-0. The pin controller's "usb" group is MICN_R_D /
		 * MICP_R_D muxed to USB_OVRCUR / USB_POWER_EN -- host-side
		 * overcurrent and VBUS-enable signals. The vendor board dts
		 * never claims them either, and both pads use the EN/SE pull
		 * encoding the section 1.4 trap is about.
		 *
		 * snps,dis-u2-freeclk-exists-quirk is carried over from the
		 * vendor node verbatim: this integration has no USB2 free
		 * running clock, and telling the core otherwise makes it wait
		 * for one that never ticks.
		 */
		usb: usb@8000000 {
			compatible = AX630C_DWC3_COMPAT;
			#address-cells = <2>;
			#size-cells = <2>;
			/*
			 * An explicit identity translation of the core's own
			 * window rather than a bare `ranges;`. Both describe
			 * the same hardware, but dtc's simple_bus_reg check
			 * cannot derive an address from an empty ranges and
			 * warns -- upstream board files hit this too and the
			 * kernel's own dtc invocation simply disables the
			 * check. Spelling the window out keeps our build
			 * warning-free without turning a check off.
			 */
			ranges = <0x0 0x8000000 0x0 0x8000000 0x0 0x100000>;
			clocks = <&flash_clk AX630C_BUS_CLK_USB_EB>,
				 <&flash_clk AX630C_USB_REF_ALT_CLK_EB>;
			clock-names = "bus", "ref_alt";
			resets = <&flash_clk AX630C_RST_FLASH_USB2_PHY>,
				 <&flash_clk AX630C_RST_FLASH_USB2_VCC>;
			reset-names = "phy", "vcc";
			axera,flash-syscon = <&flash_clk>;
			status = "okay";

			dwc3: usb@8000000 {
				compatible = "snps,dwc3";
				reg = <0x0 0x8000000 0x0 0x100000>;
				interrupts = <GIC_SPI 76 IRQ_TYPE_LEVEL_HIGH>;
				clocks = <&flash_clk AX630C_CLK_USB_REF_EB>;
				clock-names = "ref";
				dr_mode = "peripheral";
				phy_type = "utmi";
				maximum-speed = "high-speed";
				snps,dis-u2-freeclk-exists-quirk;
			};
		};

		/*
		 * DesignWare APB UARTs. 8250_dw binds these unmodified; the
		 * vendor's 8250_axera.c is a fork of it. clock-frequency
		 * replaces a clocks phandle until the clk driver lands (#80).
		 *
		 * uart0 is the debug console on hidden pads; uart1 is the
		 * accessible header (pkgs/boot.nix routes the SD debug console
		 * there). Neither is a working console on this unit -- see
		 * "No serial on this unit" -- but earlycon is the only thing
		 * that could ever explain an early hang.
		 */
		uart0: serial@4880000 {
			compatible = "snps,dw-apb-uart";
			reg = <0x0 0x4880000 0x0 0x400>;
			reg-shift = <2>;
			reg-io-width = <4>;
			clock-frequency = <208000000>;
			interrupts = <GIC_SPI 118 IRQ_TYPE_LEVEL_HIGH>;
			pinctrl-names = "default";
			pinctrl-0 = <&uart0_pins>;
			status = "okay";
		};

		uart1: serial@4881000 {
			compatible = "snps,dw-apb-uart";
			reg = <0x0 0x4881000 0x0 0x400>;
			reg-shift = <2>;
			reg-io-width = <4>;
			clock-frequency = <208000000>;
			interrupts = <GIC_SPI 119 IRQ_TYPE_LEVEL_HIGH>;
			pinctrl-names = "default";
			pinctrl-0 = <&uart1_pins>;
			status = "disabled";
		};

		/*
		 * SPI2 (#84), the mini-display's bus. Stock Synopsys
		 * DesignWare SSI; mainline spi-dw-mmio binds the unmodified
		 * compatible.
		 *
		 * ONE reset name matters. Mainline takes `reset-names = "spi"`
		 * and nothing else, so the block's APB reset is described but
		 * never touched; firmware leaves both deasserted (SW_RST2 is
		 * zero on this board) and pulsing the APB reset of a running
		 * block is not something a driver should do at probe anyway.
		 *
		 * TWO clocks, and the first is unnamed as far as the driver is
		 * concerned: spi-dw-mmio does clk_get(dev, NULL), which takes
		 * index 0 whatever clock-names says, and clk_get_rate() on it
		 * is the bus's reference. That is 208 MHz here -- the same
		 * constant the vendor driver hardcodes, which is how the
		 * source mux's index 3 is cited rather than guessed
		 * (pkgs/kernel-mainline/tree/drivers/clk/axera/clk-ax630c-tables.c).
		 *
		 * No `dmas`. The vendor node has them and its SPI master is a
		 * fork with a 32-bit endian swap in the DMA path that the
		 * panel driver then had to undo in software. PIO over the
		 * 4 KiB txbuf is 110 KB per frame at a few frames a second.
		 */
		spi2: spi@6072000 {
			compatible = "snps,dw-apb-ssi";
			reg = <0x0 0x6072000 0x0 0x400>;
			interrupts = <GIC_SPI 153 IRQ_TYPE_LEVEL_HIGH>;
			clocks = <&periph_clk AX630C_CLK_SPI_M2_EB>,
				 <&periph_clk AX630C_PCLK_SPI_M2_EB>;
			clock-names = "ssi_clk", "pclk";
			resets = <&periph_clk AX630C_RST_PERIPH_SPI2>,
				 <&periph_clk AX630C_RST_PERIPH_SPI2_PRST>;
			reset-names = "spi", "prst";
			pinctrl-names = "default";
			pinctrl-0 = <&spi2_pins>;
			num-cs = <2>;
			#address-cells = <1>;
			#size-cells = <0>;
			status = "disabled";
		};

		/*
		 * PWM0 (#84), the backlight's controller -- a DesignWare APB
		 * timer block in PWM mode. Upstream has the core and a
		 * device-tree binding that no driver matched until
		 * drivers/pwm/pwm-dwc-of.c.
		 *
		 * The clock chain is worth stating because it is not
		 * PWM-shaped: the block's source mux and class gate are the
		 * TIMER ones (the vendor node names them by register offset,
		 * clk-sel-offset = <0xD> and clk-glb-eb-offset = <0x9>), and
		 * only the per-channel gate and the APB gate belong to PWM.
		 * So "timer" here is clk_pwm00_eb, whose parent chain reaches
		 * clk_timer_sel -- 24 MHz on this board, which is exactly the
		 * constant the vendor driver hardcodes.
		 *
		 * No assigned-clock-parents: firmware already selects the
		 * 24 MHz source (CLK_MUX0 bit 13 reads 1), and clk_timer_sel
		 * is shared with the system APB timers.
		 */
		pwm0: pwm@6060000 {
			compatible = "snps,dw-apb-timers-pwm2";
			reg = <0x0 0x6060000 0x0 0x400>;
			#pwm-cells = <3>;
			clocks = <&periph_clk AX630C_PCLK_PWM0_EB>,
				 <&periph_clk AX630C_CLK_PWM00_EB>;
			clock-names = "bus", "timer";
			resets = <&periph_clk AX630C_RST_PERIPH_PWM0_PWM>,
				 <&periph_clk AX630C_RST_PERIPH_PWM0_PWM_CH0>;
			pinctrl-names = "default";
			pinctrl-0 = <&pwm0_pins>;
			status = "disabled";
		};

		/*
		 * I2S slave 0 (#84) -- the HDMI audio the LT6911UXC recovers
		 * and clocks out. Stock Synopsys DesignWare I2S, in PIO mode.
		 *
		 * PIO, NOT DMA, and the driver decides that purely from this
		 * node: mainline's dwc-i2s picks the PIO PCM when the node has
		 * `interrupts` and dmaengine when it does not. DMA here would
		 * mean porting `axera,dma-per`, a 1317-line vendor engine, for
		 * 48 kHz stereo -- which at this block's FIFO threshold is
		 * 6-12 k interrupts a second, tens of MMIO accesses each.
		 *
		 * THREE INTEGRATION FACTS the stock driver has no way to know,
		 * each an optional property added by patch 0003:
		 *
		 *  - `snps,syscon` writes the peripheral syscon's audio
		 *    crossbar word at +0x3c before the block is used. The
		 *    value is the vendor board's, recomputed from its own
		 *    seventeen `i2s-*-sel` properties: exter-codec-en (bit
		 *    19), s-rx0-sel = 3 (bits 10:9) and s-sclk-sel = 1 (bits
		 *    6:5). Masked, not the vendor's full-word write, so the
		 *    top byte survives. One writer: every other I2S instance
		 *    on this SoC shares this register and none is enabled.
		 *
		 *  - `snps,rx-channel = <1>`. That crossbar setting lands the
		 *    stream on the block's RX channel 1, not 0 -- the vendor
		 *    driver carries a hardcoded `if (rx0_sel == 3) enable
		 *    RER(1)` for exactly this. The stock driver assumes
		 *    channel 0 in four places and would wait forever for an
		 *    interrupt that is masked.
		 *
		 *  - `apb`. In slave mode the driver takes no clock at all,
		 *    having no bit clock to program, so without naming the APB
		 *    gate clk_disable_unused() takes the register window away
		 *    partway through boot. The reference gate is named too,
		 *    because whether a pure slave needs it is not established.
		 *
		 * ONE reset, matching the vendor's `hdmi-i2s` path, which
		 * deliberately requests only "rst" and leaves the APB reset
		 * alone. Mainline deasserts every entry in `resets` together,
		 * so listing the second one would be a behaviour change
		 * nobody has tested.
		 */
		i2s_slv0: i2s@6051000 {
			compatible = "snps,designware-i2s";
			reg = <0x0 0x6051000 0x0 0x400>;
			interrupts = <GIC_SPI 145 IRQ_TYPE_LEVEL_HIGH>;
			clocks = <&periph_clk AX630C_PCLK_I2S_S_EB>,
				 <&periph_clk AX630C_CLK_I2S_REF0_EB>;
			clock-names = "apb", "mclk";
			resets = <&periph_clk AX630C_RST_PERIPH_I2S_SLV0>;
			pinctrl-names = "default";
			pinctrl-0 = <&i2s0_pins>;
			snps,syscon = <&periph_clk 0x3c 0x00ffffff 0x00080620>;
			snps,rx-channel = <1>;
			#sound-dai-cells = <0>;
			status = "disabled";
		};

		/*
		 * Watchdog 0. Boot-critical, and the reason a mainline kernel
		 * can boot this board at all: U-Boot arms this block for 30 s
		 * immediately before `booti`, so a kernel that does not pet it
		 * is hard-reset about a minute in, with no console to say why.
		 *
		 * One reg window, not two. The vendor node's second window is
		 * the peripheral syscon, which the clock controller above
		 * already owns -- two request_mem_region()s over one window
		 * cannot both succeed. The block's two clocks, its two resets
		 * and its counter-source mux are all bits in that window, so
		 * they are named here as clocks and resets of the peripheral
		 * controller and the driver never maps the window at all.
		 *
		 * assigned-clock-parents selects the 24 MHz source. Firmware
		 * already selects it, so on this board the write never happens
		 * (clk_set_parent() is a no-op when the parent matches) -- but
		 * stating it means the timeout arithmetic and the hardware
		 * agree on any board whose firmware differs, because the driver
		 * takes its rate from clk_get_rate() rather than a constant.
		 * The other source is the 32768 Hz RTC output, and both rates
		 * are measured, not assumed.
		 *
		 * The interrupt is described because the hardware raises it at
		 * the first of the block's two expiry stages, but the driver
		 * does not claim it: a pretimeout structurally fixed at
		 * timeout/2 is not something the watchdog core can express.
		 */
		wdt0: watchdog@4840000 {
			compatible = AX630C_WDT_COMPAT;
			reg = <0x0 0x4840000 0x0 0x400>;
			interrupts = <GIC_SPI 149 IRQ_TYPE_LEVEL_HIGH>;
			clocks = <&periph_clk AX630C_CLK_WDT0_EB>,
				 <&periph_clk AX630C_PCLK_WDT0_EB>;
			clock-names = "wdt", "apb";
			assigned-clocks = <&periph_clk AX630C_CLK_WDT0_SEL>;
			assigned-clock-parents = <&common_clk AX630C_CPLL_24M>;
			resets = <&periph_clk AX630C_RST_PERIPH_WDT0_ARST>,
				 <&periph_clk AX630C_RST_PERIPH_WDT0_PRST>;
			reset-names = "wdt", "apb";
			status = "okay";
		};

		/*
		 * ===============================================================
		 * Video (#83). The KVM's data path: HDMI bridge -> CSI-2 -> VIN
		 * -> DDR -> VC8000E. Everything here is disabled by default and
		 * enabled by the board, because only a board knows whether it
		 * has a bridge on the other end of the lanes.
		 * ===============================================================
		 */

		/*
		 * The ISP syscon. This is the vendor's ninth clock window, the
		 * one the #80 model dropped because nothing has ever
		 * implemented it as a clock provider -- and that is still true.
		 * What it actually carries, for our purposes, is the CSI
		 * receiver's clock gates and soft resets (+0xc8..+0xe4), its
		 * deskew-lock status (+0xc4), the controller select (+0x218),
		 * and, in its first 0x100, the VIN/ISP clock-source mux and the
		 * two reset groups the capture driver sweeps.
		 *
		 * So it is a plain syscon shared by the two drivers, each
		 * writing single-bit SET/CLR or VALUE/MASK strobes -- never a
		 * read-modify-write of a shared word. A `syscon` node maps
		 * nothing until someone asks for the regmap, so declaring it
		 * cannot itself touch an unclocked block.
		 */
		isp_syscon: syscon@2500000 {
			compatible = AX630C_ISP_SYSCON_COMPAT, "syscon";
			reg = <0x0 0x2500000 0x0 0x10000>;
		};

		/*
		 * MIPI CSI-2 receiver. Two reg windows: the protocol
		 * controllers (two of them, 0x2000 apart, of which this board
		 * uses dev0) and the D-PHY global file. On 4.19 the second was
		 * an ioremap of a literal address, which is exactly the kind of
		 * thing a port is supposed to delete.
		 *
		 * The error interrupt is per controller. csictrl1 is described
		 * because the hardware has it; the driver claims only
		 * csictrl0, because dev1 is unused here.
		 *
		 * One clock and one reset, both bits in the common syscon that
		 * the 4.19 driver strobed by hand. Taking them properly is not
		 * cosmetic: clk_disable_unused() gates an unclaimed clock on
		 * mainline, and mainline U-Boot enables nothing.
		 */
		mipi_rx: csi2-rx@2600000 {
			compatible = AX630C_CSI2RX_COMPAT;
			reg = <0x0 0x2600000 0x0 0x4000>,
			      <0x0 0x23f0000 0x0 0x1000>;
			reg-names = "csi", "dphy";
			interrupts = <GIC_SPI 31 IRQ_TYPE_LEVEL_HIGH>,
				     <GIC_SPI 33 IRQ_TYPE_LEVEL_HIGH>;
			interrupt-names = "csictrl0", "csictrl1";
			clocks = <&common_clk AX630C_CLK_DPHYRX_TLB_EB>;
			clock-names = "dphyrx_tlb";
			resets = <&common_clk AX630C_RST_COMM_DPHYRX_TLB>;
			reset-names = "dphyrx_tlb";
			axera,isp-syscon = <&isp_syscon>;
			axera,common-syscon = <&common_clk>;
			pinctrl-names = "default";
			pinctrl-0 = <&mipi_rx_pins>;
			status = "disabled";

			ports {
				#address-cells = <1>;
				#size-cells = <0>;

				/*
				 * From the board's source. Empty here on
				 * purpose: what feeds these lanes, and which
				 * physical lane carries which logical one, is
				 * a board fact, and the receiver reads its
				 * lane map out of this endpoint.
				 */
				csi2_port0: port@0 {
					reg = <0>;
				};

				/* To the VIN capture block. */
				port@1 {
					reg = <1>;

					csi2_out: endpoint {
						remote-endpoint = <&vin_in>;
					};
				};
			};
		};

		/*
		 * VIN/IFE capture. One 1 MiB window covering the whole ISP
		 * register file; the driver uses the SIF front end, the IFE
		 * bypass path and one WDMA channel of it.
		 *
		 * Two interrupts, both described, of which the driver claims
		 * the first: the frame-done line. The VI and ISP-MM domain
		 * gates are clocks here for the same reason the receiver's is.
		 *
		 * memory-region is the capture buffer pool -- see the board's
		 * reserved-memory for why it sits where it does.
		 */
		vin: video-capture@2400000 {
			compatible = AX630C_VIN_COMPAT;
			reg = <0x0 0x2400000 0x0 0x100000>;
			interrupts = <GIC_SPI 27 IRQ_TYPE_LEVEL_HIGH>,
				     <GIC_SPI 28 IRQ_TYPE_LEVEL_HIGH>;
			clocks = <&common_clk AX630C_CLK_VI_EB>,
				 <&common_clk AX630C_CLK_ISP_MM_EB>;
			clock-names = "vi", "isp_mm";
			axera,isp-syscon = <&isp_syscon>;
			status = "disabled";

			port {
				vin_in: endpoint {
					remote-endpoint = <&csi2_out>;
				};
			};
		};

		/*
		 * VC8000E encoder command engine. The core register file sits
		 * at +0x1000 inside this window; the engine reports
		 * hw_version_id 0x43421500 (VCMD v1.5.0).
		 *
		 * The block comes out of a cold boot IN RESET, and its clock
		 * alone is not enough -- clocked but held in reset the whole
		 * window reads the 0xDEADBEEF bus poison (device-proven
		 * 2026-08-31). So `resets` here is load-bearing, and it is the
		 * first consumer of the #80 reset provider's .deassert.
		 */
		venc: video-encoder@4010000 {
			compatible = AX630C_VC8000E_COMPAT;
			reg = <0x0 0x4010000 0x0 0x10000>;
			interrupts = <GIC_SPI 93 IRQ_TYPE_LEVEL_HIGH>;
			clocks = <&vpu_clk AX630C_CLK_VENC_EB>;
			resets = <&vpu_clk AX630C_RST_VPU_VENC>;
			status = "disabled";
		};
	};

	/*
	 * Reboot. PSCI on this TF-A implements no SYSTEM_RESET -- psci_sys_reset
	 * still registers at priority 129, makes one SMC that returns
	 * NOT_SUPPORTED, and falls through -- so the chip reset has to come from
	 * somewhere else. CHIP_RST_SW is bit 0 of COMM_ABORT_CFG in the common
	 * syscon, which is what the vendor U-Boot's own reboot uses; poking it
	 * from the running vendor system resets the SoC through the whole boot
	 * chain and leaves the A/B slot register intact (verified on hardware
	 * 2026-09-06).
	 *
	 * mask and value are both given so the driver does a read-modify-write.
	 * With mask alone it writes the whole word, which would clear the wdt0
	 * and wdt2 reset enables in bits 7 and 9 -- disarming the fallback on
	 * the way out.
	 *
	 * Priority 192 by default, ahead of PSCI's 129; the watchdog's own
	 * restart handler sits behind both at 128.
	 */
	reboot {
		compatible = "syscon-reboot";
		regmap = <&common_clk>;
		offset = <0xa8>;
		mask = <0x1>;
		value = <0x1>;
	};
};
